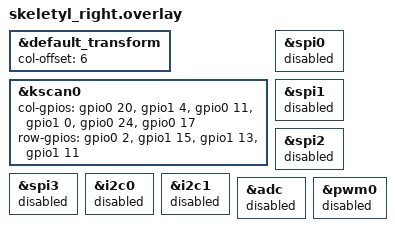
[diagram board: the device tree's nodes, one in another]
#include "skeletyl_matrix.dtsi"

&default_transform {
	col-offset = <6>;
};

&kscan0 {
	col-gpios =
		<&gpio0 20 GPIO_ACTIVE_HIGH>
		, <&gpio1 4 GPIO_ACTIVE_HIGH>
		, <&gpio0 11 GPIO_ACTIVE_HIGH>
		, <&gpio1 0 GPIO_ACTIVE_HIGH>
		, <&gpio0 24 GPIO_ACTIVE_HIGH>
		, <&gpio0 17 GPIO_ACTIVE_HIGH>
		;
	row-gpios =
		<&gpio0 2 (GPIO_ACTIVE_HIGH | GPIO_PULL_DOWN)>
		, <&gpio1 15 (GPIO_ACTIVE_HIGH | GPIO_PULL_DOWN)>
		, <&gpio1 13 (GPIO_ACTIVE_HIGH | GPIO_PULL_DOWN)>
		, <&gpio1 11 (GPIO_ACTIVE_HIGH | GPIO_PULL_DOWN)>
		;
};

&spi0 { status = "disabled"; };
&spi1 { status = "disabled"; };
&spi2 { status = "disabled"; };
&spi3 { status = "disabled"; };
&i2c0 { status = "disabled"; };
&i2c1 { status = "disabled"; };
&adc { status = "disabled"; };
&pwm0 { status = "disabled"; };
